AUTOSAR XML (schema 4-2-2)
package /ComponentTypes
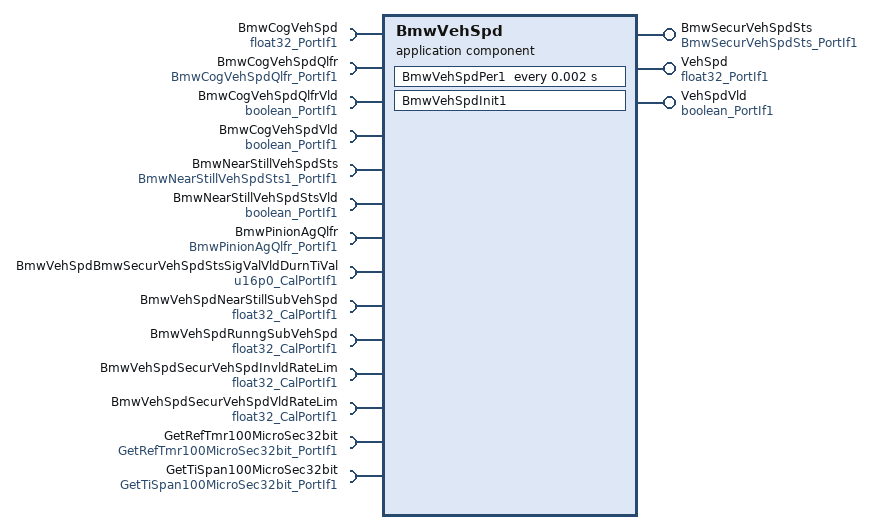
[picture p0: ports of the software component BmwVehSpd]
  application sw component type BmwVehSpd
    provide port BmwSecurVehSpdSts: nonqueued-sender-com-spec{data-element=Val, init-value=15}, provided-interface=BmwSecurVehSpdSts_PortIf1
    provide port VehSpd: nonqueued-sender-com-spec{data-element=Val, init-value=0}, provided-interface=float32_PortIf1
    provide port VehSpdVld: nonqueued-sender-com-spec{data-element=Logl, init-value=0}, provided-interface=boolean_PortIf1
    14 x require port:
      BmwCogVehSpd: nonqueued-receiver-com-spec{data-element=Val, filter=data-filter-type=ALWAYS, init-value=0}, required-interface=float32_PortIf1
      BmwCogVehSpdQlfr: nonqueued-receiver-com-spec{data-element=Val, filter=data-filter-type=ALWAYS, init-value=15}, required-interface=BmwCogVehSpdQlfr_PortIf1
      BmwCogVehSpdQlfrVld: nonqueued-receiver-com-spec{data-element=Logl, filter=data-filter-type=ALWAYS, init-value=0}, required-interface=boolean_PortIf1
      BmwCogVehSpdVld: nonqueued-receiver-com-spec{data-element=Logl, filter=data-filter-type=ALWAYS, init-value=0}, required-interface=boolean_PortIf1
      BmwNearStillVehSpdSts: nonqueued-receiver-com-spec{data-element=Val, filter=data-filter-type=ALWAYS, init-value=15}, required-interface=BmwNearStillVehSpdSts1_PortIf1
      BmwNearStillVehSpdStsVld: nonqueued-receiver-com-spec{data-element=Logl, filter=data-filter-type=ALWAYS, init-value=0}, required-interface=boolean_PortIf1
      BmwPinionAgQlfr: nonqueued-receiver-com-spec{data-element=Val, filter=data-filter-type=ALWAYS, init-value=14}, required-interface=BmwPinionAgQlfr_PortIf1
      BmwVehSpdBmwSecurVehSpdStsSigValVldDurnTiVal: parameter-require-com-spec{init-value=300, parameter=Val}, required-interface=u16p0_CalPortIf1
      BmwVehSpdNearStillSubVehSpd: parameter-require-com-spec{init-value=9, parameter=Val}, required-interface=float32_CalPortIf1
      BmwVehSpdRunngSubVehSpd: parameter-require-com-spec{init-value=130, parameter=Val}, required-interface=float32_CalPortIf1
      BmwVehSpdSecurVehSpdInvldRateLim: parameter-require-com-spec{init-value=50, parameter=Val}, required-interface=float32_CalPortIf1
      BmwVehSpdSecurVehSpdVldRateLim: parameter-require-com-spec{init-value=50, parameter=Val}, required-interface=float32_CalPortIf1
      GetRefTmr100MicroSec32bit: client-com-spec=Oper, required-interface=GetRefTmr100MicroSec32bit_PortIf1
      GetTiSpan100MicroSec32bit: client-com-spec=Oper, required-interface=GetTiSpan100MicroSec32bit_PortIf1
    behavior BmwVehSpd_InternalBehavior
      ar-typed-per-instance-memorys:
        data BmwSecurVehSpdStsSigValVldDurn: sw-calibration-access=READ-ONLY, type=uint32
        data SpdDifChkFlg: sw-calibration-access=READ-ONLY, type=boolean
        data VehSpdLimPrev: sw-calibration-access=READ-ONLY, type=float32
      init event BmwVehSpd_InitEvent: start-on-event=BmwVehSpdInit1
      timing event TMT_BmwVehSpdPer1: start-on-event=BmwVehSpdPer1, period=0.002
      port-api-options:
        enable-take-address=false, error-handling=NO-TRANSFORMER-ERROR-HANDLING, indirect-api=false, port=BmwCogVehSpd
        enable-take-address=false, error-handling=NO-TRANSFORMER-ERROR-HANDLING, indirect-api=false, port=BmwCogVehSpdQlfr
        enable-take-address=false, error-handling=NO-TRANSFORMER-ERROR-HANDLING, indirect-api=false, port=BmwCogVehSpdQlfrVld
        enable-take-address=false, error-handling=NO-TRANSFORMER-ERROR-HANDLING, indirect-api=false, port=BmwCogVehSpdVld
        enable-take-address=false, error-handling=NO-TRANSFORMER-ERROR-HANDLING, indirect-api=false, port=BmwNearStillVehSpdSts
        enable-take-address=false, error-handling=NO-TRANSFORMER-ERROR-HANDLING, indirect-api=false, port=BmwNearStillVehSpdStsVld
        enable-take-address=false, error-handling=NO-TRANSFORMER-ERROR-HANDLING, indirect-api=false, port=BmwPinionAgQlfr
        enable-take-address=false, error-handling=NO-TRANSFORMER-ERROR-HANDLING, indirect-api=false, port=BmwSecurVehSpdSts
        enable-take-address=false, error-handling=NO-TRANSFORMER-ERROR-HANDLING, indirect-api=false, port=BmwVehSpdBmwSecurVehSpdStsSigValVldDurnTiVal
        enable-take-address=false, error-handling=NO-TRANSFORMER-ERROR-HANDLING, indirect-api=false, port=BmwVehSpdNearStillSubVehSpd
        enable-take-address=false, error-handling=NO-TRANSFORMER-ERROR-HANDLING, indirect-api=false, port=BmwVehSpdRunngSubVehSpd
        enable-take-address=false, error-handling=NO-TRANSFORMER-ERROR-HANDLING, indirect-api=false, port=BmwVehSpdSecurVehSpdInvldRateLim
        enable-take-address=false, error-handling=NO-TRANSFORMER-ERROR-HANDLING, indirect-api=false, port=BmwVehSpdSecurVehSpdVldRateLim
        enable-take-address=false, error-handling=NO-TRANSFORMER-ERROR-HANDLING, indirect-api=false, port=GetRefTmr100MicroSec32bit
        enable-take-address=false, error-handling=NO-TRANSFORMER-ERROR-HANDLING, indirect-api=false, port=GetTiSpan100MicroSec32bit
        enable-take-address=false, error-handling=NO-TRANSFORMER-ERROR-HANDLING, indirect-api=false, port=VehSpd
        enable-take-address=false, error-handling=NO-TRANSFORMER-ERROR-HANDLING, indirect-api=false, port=VehSpdVld
      runnable BmwVehSpdInit1
      runnable BmwVehSpdPer1
        data-receive-point-by-arguments:
          7 x access:
            REC_BmwCogVehSpd_Val: accessed-variable=BmwCogVehSpd.Val
            REC_BmwCogVehSpdQlfr_Val: accessed-variable=BmwCogVehSpdQlfr.Val
            REC_BmwCogVehSpdQlfrVld_Logl: accessed-variable=BmwCogVehSpdQlfrVld.Logl
            REC_BmwCogVehSpdVld_Logl: accessed-variable=BmwCogVehSpdVld.Logl
            REC_BmwNearStillVehSpdSts_Val: accessed-variable=BmwNearStillVehSpdSts.Val
            REC_BmwNearStillVehSpdStsVld_Logl: accessed-variable=BmwNearStillVehSpdStsVld.Logl
            REC_BmwPinionAgQlfr_Val: accessed-variable=BmwPinionAgQlfr.Val
        data-send-points:
          access SEND_BmwSecurVehSpdSts_Val: accessed-variable=BmwSecurVehSpdSts.Val
          access SEND_VehSpd_Val: accessed-variable=VehSpd.Val
          access SEND_VehSpdVld_Logl: accessed-variable=VehSpdVld.Logl
        sync call SC_GetRefTmr100MicroSec32bit_Oper: operation=GetRefTmr100MicroSec32bit.Oper, timeout=0
        sync call SC_GetTiSpan100MicroSec32bit_Oper: operation=GetTiSpan100MicroSec32bit.Oper, timeout=0
  swc implementation BmwVehSpd_Implementation: behavior=BmwVehSpd_InternalBehavior
    code-descriptors:
      code Default: artifact-descriptors=autosar-engineering-object={short-label=Default, category=SWSRC}
